# MK21D5WS register map
File version: 1.6
Registers are 32-bit, read-write, reset 0x0 unless marked. A register's access mark holds for its fields unless they carry their own. Offsets are from the block's base; [hi:lo] are bit positions; {n}, {i} and the like mark numbered series.

## SMC — System Mode Controller
Base 0x4007E000; register names take the prefix SMC_
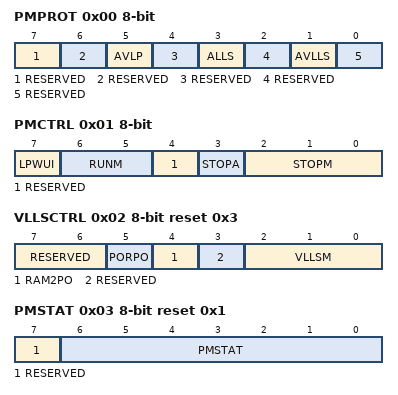
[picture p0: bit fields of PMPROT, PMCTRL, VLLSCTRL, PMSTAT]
0x00 PMPROT 8-bit — Power Mode Protection register
  [7] RESERVED ro
  [6] RESERVED ro
  [5] AVLP — Allow Very-Low-Power Modes
    0=VLPR, VLPW and VLPS are not allowed; 1=VLPR, VLPW and VLPS are allowed
  [4] RESERVED ro
  [3] ALLS — Allow Low-Leakage Stop Mode
    0=Any LLSx mode is not allowed; 1=Any LLSx mode is allowed
  [2] RESERVED ro
  [1] AVLLS — Allow Very-Low-Leakage Stop Mode
    0=Any VLLSx mode is not allowed; 1=Any VLLSx mode is allowed
  [0] RESERVED ro
0x01 PMCTRL 8-bit — Power Mode Control register
  [7] LPWUI — Low-Power Wake Up On Interrupt
    0=The system remains in a VLP mode on an interrupt; 1=The system exits to Normal RUN mode on an interrupt
  [6:5] RUNM — Run Mode Control
    0=Normal Run mode (RUN); 2=Very-Low-Power Run mode (VLPR)
  [4] RESERVED ro
  [3] STOPA ro — Stop Aborted
    0=The previous stop mode entry was successsful; 1=The previous stop mode entry was aborted
  [2:0] STOPM — Stop Mode Control
    0=Normal Stop (STOP); 2=Very-Low-Power Stop (VLPS); 3=Low-Leakage Stop (LLSx); 4=Very-Low-Leakage Stop (VLLSx); 6=Reseved
0x02 VLLSCTRL 8-bit reset 0x3 — VLLS Control register
  [7:6] RESERVED ro
  [5] PORPO — POR Power Option
    0=POR detect circuit is enabled in VLLS0; 1=POR detect circuit is disabled in VLLS0
  [4] RAM2PO — RAM2 Power Option
    0=RAM2 not powered in VLLS2; 1=RAM2 powered in VLLS2
  [3] RESERVED ro
  [2:0] VLLSM — VLLS Mode Control
    {v}=VLLS{v} (v=0..3)
0x03 PMSTAT 8-bit ro reset 0x1 — Power Mode Status register
  [7] RESERVED, [6:0] PMSTAT

## RCM — Reset Control Module
Base 0x4007F000; register names take the prefix RCM_
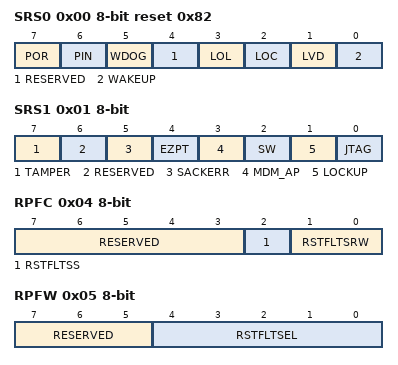
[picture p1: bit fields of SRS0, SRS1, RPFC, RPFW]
0x00 SRS0 8-bit ro reset 0x82 — System Reset Status Register 0
  [7] POR — Power-On Reset
    0=Reset not caused by POR; 1=Reset caused by POR
  [6] PIN — External Reset Pin
    0=Reset not caused by external reset pin; 1=Reset caused by external reset pin
  [5] WDOG — Watchdog
    0=Reset not caused by watchdog timeout; 1=Reset caused by watchdog timeout
  [4] RESERVED
  [3] LOL — Loss-of-Lock Reset
    0=Reset not caused by a loss of lock in the PLL; 1=Reset caused by a loss of lock in the PLL
  [2] LOC — Loss-of-Clock Reset
    0=Reset not caused by a loss of external clock; 1=Reset caused by a loss of external clock
  [1] LVD — Low-Voltage Detect Reset
    0=Reset not caused by LVD trip or POR; 1=Reset caused by LVD trip or POR
  [0] WAKEUP — Low Leakage Wakeup Reset
    0=Reset not caused by LLWU module wakeup source; 1=Reset caused by LLWU module wakeup source
0x01 SRS1 8-bit ro — System Reset Status Register 1
  [7] TAMPER — Tamper detect
    0=Reset not caused by tamper detect; 1=Reset caused by tamper detect
  [6] RESERVED
  [5] SACKERR — Stop Mode Acknowledge Error Reset
    0=Reset not caused by peripheral failure to acknowledge attempt to enter stop mode; 1=Reset caused by peripheral failure to acknowledge attempt to enter stop mode
  [4] EZPT — EzPort Reset
    0=Reset not caused by EzPort receiving the RESET command while the device is in EzPort mode; 1=Reset caused by EzPort receiving the RESET command while the device is in EzPort mode
  [3] MDM_AP — MDM-AP System Reset Request
    0=Reset not caused by host debugger system setting of the System Reset Request bit; 1=Reset caused by host debugger system setting of the System Reset Request bit
  [2] SW — Software
    0=Reset not caused by software setting of SYSRESETREQ bit; 1=Reset caused by software setting of SYSRESETREQ bit
  [1] LOCKUP — Core Lockup
    0=Reset not caused by core LOCKUP event; 1=Reset caused by core LOCKUP event
  [0] JTAG — JTAG Generated Reset
    0=Reset not caused by JTAG; 1=Reset caused by JTAG
0x04 RPFC 8-bit — Reset Pin Filter Control register
  [7:3] RESERVED ro
  [2] RSTFLTSS — Reset Pin Filter Select in Stop Mode
    0=All filtering disabled; 1=LPO clock filter enabled
  [1:0] RSTFLTSRW — Reset Pin Filter Select in Run and Wait Modes
    0=All filtering disabled; 1=Bus clock filter enabled for normal operation; 2=LPO clock filter enabled for normal operation
0x05 RPFW 8-bit — Reset Pin Filter Width register
  [7:5] RESERVED ro
  [4:0] RSTFLTSEL — Reset Pin Filter Bus Clock Select
    {v}=Bus clock filter count is {v+1} (v=0..31)
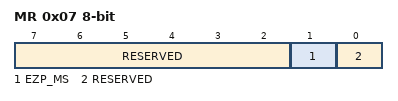
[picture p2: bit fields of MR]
0x07 MR 8-bit ro — Mode Register
  [7:2] RESERVED
  [1] EZP_MS — EZP_MS_B pin state
    0=Pin deasserted (logic 1); 1=Pin asserted (logic 0)
  [0] RESERVED

## PTA — General Purpose Input/Output
Base 0x400FF000; register names take the prefix GPIOA_
0x00 PDOR — Port Data Output Register
  [31:0] PDO — Port Data Output
    0=Logic level 0 is driven on pin, provided pin is configured for general-purpose output; 1=Logic level 1 is driven on pin, provided pin is configured for general-purpose output
0x04 PSOR wo — Port Set Output Register
  [31:0] PTSO — Port Set Output
    0=Corresponding bit in PDORn does not change; 1=Corresponding bit in PDORn is set to logic 1
0x08 PCOR wo — Port Clear Output Register
  [31:0] PTCO — Port Clear Output
    0=Corresponding bit in PDORn does not change; 1=Corresponding bit in PDORn is cleared to logic 0
0x0C PTOR wo — Port Toggle Output Register
  [31:0] PTTO — Port Toggle Output
    0=Corresponding bit in PDORn does not change; 1=Corresponding bit in PDORn is set to the inverse of its existing logic state
0x10 PDIR ro — Port Data Input Register
  [31:0] PDI — Port Data Input
    0=Pin logic level is logic 0, or is not configured for use by digital function; 1=Pin logic level is logic 1
0x14 PDDR — Port Data Direction Register
  [31:0] PDD — Port Data Direction
    0=Pin is configured as general-purpose input, for the GPIO function; 1=Pin is configured as general-purpose output, for the GPIO function

## PTB — General Purpose Input/Output
Base 0x400FF040; register names take the prefix GPIOB_
Registers as PTA.

## PTC — General Purpose Input/Output
Base 0x400FF080; register names take the prefix GPIOC_
Registers as PTA; these are added or differ:
0x08 PCOR wo — Port Clear Output Register
  [31:0] PTCO — Port Clear Output
    0=Corresponding bit in PDORn does not change; 1=Corresponding bit in PDORn is cleared to logic 0

## PTD — General Purpose Input/Output
Base 0x400FF0C0; register names take the prefix GPIOD_
Registers as PTA.

## PTE — General Purpose Input/Output
Base 0x400FF100; register names take the prefix GPIOE_
Registers as PTA.

## MCM — Core Platform Miscellaneous Control Module
Base 0xE0080000; register names take the prefix MCM_
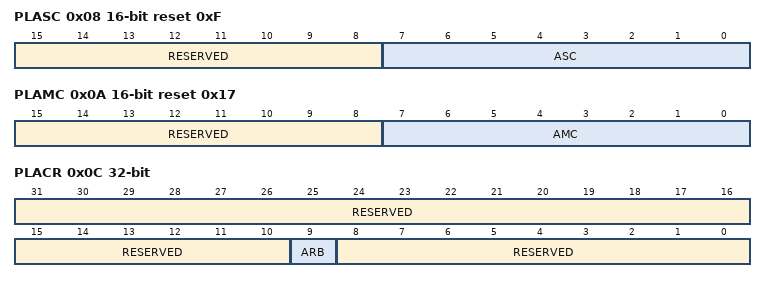
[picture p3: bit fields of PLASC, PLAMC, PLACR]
0x08 PLASC 16-bit ro reset 0xF — Crossbar Switch (AXBS) Slave Configuration
  [15:8] RESERVED
  [7:0] ASC — Each bit in the ASC field indicates whether there is a corresponding connection to the crossbar switch's slave input port.
    0=A bus slave connection to AXBS input port n is absent; 1=A bus slave connection to AXBS input port n is present
0x0A PLAMC 16-bit ro reset 0x17 — Crossbar Switch (AXBS) Master Configuration
  [15:8] RESERVED
  [7:0] AMC — Each bit in the AMC field indicates whether there is a corresponding connection to the AXBS master input port.
    0=A bus master connection to AXBS input port n is absent; 1=A bus master connection to AXBS input port n is present
0x0C PLACR — Crossbar Switch (AXBS) Control Register
  [31:10] RESERVED ro
  [9] ARB — Arbitration select
    0=Fixed-priority arbitration for the crossbar masters; 1=Round-robin arbitration for the crossbar masters
  [8:0] RESERVED ro
